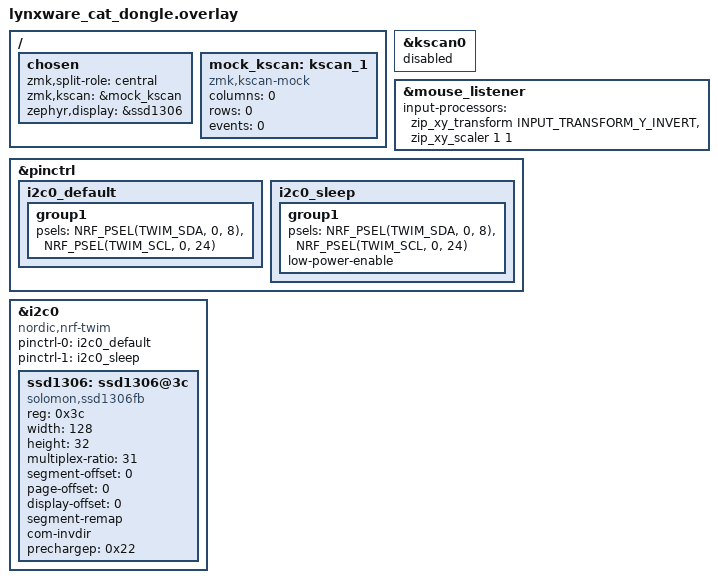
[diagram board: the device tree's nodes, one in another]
#include "lynxware_cat.dtsi"
#include <input/processors.dtsi>
#include <dt-bindings/zmk/input_transform.h>
#include <zephyr/dt-bindings/input/input-event-codes.h>

/ {
    chosen {
        zmk,split-role = "central";
        zmk,kscan = &mock_kscan;
        zephyr,display = &ssd1306;
    };

    mock_kscan: kscan_1 {
        compatible = "zmk,kscan-mock";
        columns = <0>;
        rows = <0>;
        events = <0>;
    };
};

&kscan0 {
    status = "disabled";
};

&mouse_listener {
    status = "okay";
    input-processors = <&zip_xy_transform INPUT_TRANSFORM_Y_INVERT &zip_xy_scaler 1 1>;
};

&pinctrl {
    i2c0_default: i2c0_default {
        group1 {
            psels = <NRF_PSEL(TWIM_SDA, 0, 8)>,
                    <NRF_PSEL(TWIM_SCL, 0, 24)>;
        };
    };
    i2c0_sleep: i2c0_sleep {
        group1 {
            psels = <NRF_PSEL(TWIM_SDA, 0, 8)>,
                    <NRF_PSEL(TWIM_SCL, 0, 24)>;
            low-power-enable;
        };
    };
};

&i2c0 {
    status = "okay";
    compatible = "nordic,nrf-twim";
    pinctrl-0 = <&i2c0_default>;
    pinctrl-1 = <&i2c0_sleep>;
    pinctrl-names = "default", "sleep";

    ssd1306: ssd1306@3c {
        compatible = "solomon,ssd1306fb";
        reg = <0x3c>;
        status = "okay";
        width = <128>;
        height = <32>;
        multiplex-ratio = <31>;
        segment-offset = <0>;
        page-offset = <0>;
        display-offset = <0>;
        segment-remap;
        com-invdir;
        prechargep = <0x22>;
    };
};
